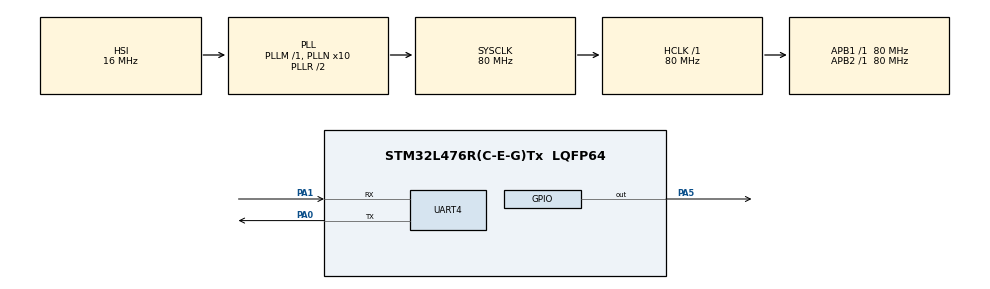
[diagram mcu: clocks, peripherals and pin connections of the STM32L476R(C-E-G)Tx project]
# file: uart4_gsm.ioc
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Dma.Request0=UART4_RX
Dma.UART4_RX.0.Direction=DMA_PERIPH_TO_MEMORY
Dma.UART4_RX.0.Instance=DMA2_Channel5
Dma.UART4_RX.0.MemDataAlignment=DMA_MDATAALIGN_BYTE
Dma.UART4_RX.0.MemInc=DMA_MINC_ENABLE
Dma.UART4_RX.0.Mode=DMA_NORMAL
Dma.UART4_RX.0.PeriphDataAlignment=DMA_PDATAALIGN_BYTE
Dma.UART4_RX.0.PeriphInc=DMA_PINC_DISABLE
Dma.UART4_RX.0.Priority=DMA_PRIORITY_LOW
Mcu.Family=STM32L4
Mcu.Name=STM32L476R(C-E-G)Tx
Mcu.Package=LQFP64
NVIC.DMA2_Channel5_IRQn=true\:0\:0\:false\:false\:true\:false\:true\:true
NVIC.PriorityGroup=NVIC_PRIORITYGROUP_4
NVIC.UART4_IRQn=true\:0\:0\:false\:false\:true\:true\:true\:true
PA0.Mode=Asynchronous
PA0.Signal=UART4_TX
PA1.Mode=Asynchronous
PA1.Signal=UART4_RX
PA5.Signal=GPIO_Output
ProjectManager.HeapSize=0x200
ProjectManager.StackSize=0x400
ProjectManager.TargetToolchain=STM32CubeIDE
RCC.ADCFreq_Value=64000000
RCC.AHBFreq_Value=80000000
RCC.APB1Freq_Value=80000000
RCC.APB1TimFreq_Value=80000000
RCC.APB2Freq_Value=80000000
RCC.APB2TimFreq_Value=80000000
RCC.CortexFreq_Value=80000000
RCC.HCLKFreq_Value=80000000
RCC.HSE_VALUE=8000000
RCC.HSI_VALUE=16000000
RCC.LSE_VALUE=32768
RCC.MSI_VALUE=4000000
RCC.PLLN=10
RCC.PLLSourceVirtual=RCC_PLLSOURCE_HSI
RCC.PREFETCH_ENABLE=1
RCC.SYSCLKFreq_VALUE=80000000
RCC.SYSCLKSource=RCC_SYSCLKSOURCE_PLLCLK
RCC.USBFreq_Value=64000000
RCC.VCOOutputFreq_Value=160000000
board=NUCLEO-L476RG

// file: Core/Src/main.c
/* USER CODE BEGIN Header */
/**
  ******************************************************************************
  * @file           : main.c
  * @brief          : Main program body
  ******************************************************************************
  * @attention
  *
  * Copyright (c) 2024 STMicroelectronics.
  * All rights reserved.
  *
  * This software is licensed under terms that can be found in the LICENSE file
  * in the root directory of this software component.
  * If no LICENSE file comes with this software, it is provided AS-IS.
  *
  ******************************************************************************
  */
/* USER CODE END Header */
#include "main.h"
#include "stdio.h"
#include "string.h"
#define RXSIZE 20
uint8_t RxBuf[30];
uint8_t string[100];
int _write(int file,char *ptr,int len)
{
    int i=0;
    for(i=0;i<len;i++)
    	ITM_SendChar((*ptr++));
    return len;
}

/* USER CODE BEGIN PTD */
UART_HandleTypeDef huart4;
/* USER CODE END PTD */

/* USER CODE BEGIN PD */
void HAL_UART_RxCpltCallback(UART_HandleTypeDef *huart)
{
  printf("Received data %s\n",RxBuf);
  memset(RxBuf,0,20);
  HAL_UART_Receive_IT(&huart4, RxBuf, 30);
}
/* USER CODE END PD */

UART_HandleTypeDef huart4;
DMA_HandleTypeDef hdma_uart4_rx;

void SystemClock_Config(void);
static void MX_GPIO_Init(void);
static void MX_DMA_Init(void);
static void MX_UART4_Init(void);

/* USER CODE BEGIN 0 */
  //  creating a buffer of 2 bytes
/* USER CODE END 0 */

int main(void)
{

  /* MCU Configuration--------------------------------------------------------*/

  /* Reset of all peripherals, Initializes the Flash interface and the Systick. */
  HAL_Init();

  /* Configure the system clock */
  SystemClock_Config();

  /* Initialize all configured peripherals */
  MX_GPIO_Init();
  MX_DMA_Init();
  MX_UART4_Init();
  /* USER CODE BEGIN 2 */
  HAL_UART_Receive_DMA(&huart4,(uint8_t *) RxBuf, 30);
  HAL_UART_Transmit(&huart4,(uint8_t *)"AT+CSQ\r\n", sizeof("AT+CSQ\r\n"), 20);
 	  printf("Sent data :AT\n");
 	  HAL_Delay (2000);
 	  HAL_GPIO_TogglePin (GPIOA, GPIO_PIN_5);
 	  HAL_Delay (250);
 	  printf("Received data :%s\n", RxBuf);
  /* USER CODE END 2 */

  /* Infinite loop */
  while (1)
  {

  }
}

void SystemClock_Config(void)
{
  RCC_OscInitTypeDef RCC_OscInitStruct = {0};
  RCC_ClkInitTypeDef RCC_ClkInitStruct = {0};

  /** Configure the main internal regulator output voltage
  */
  if (HAL_PWREx_ControlVoltageScaling(PWR_REGULATOR_VOLTAGE_SCALE1) != HAL_OK)
  {
    Error_Handler();
  }

  /** Initializes the RCC Oscillators according to the specified parameters
  * in the RCC_OscInitTypeDef structure.
  */
  RCC_OscInitStruct.OscillatorType = RCC_OSCILLATORTYPE_HSI;
  RCC_OscInitStruct.HSIState = RCC_HSI_ON;
  RCC_OscInitStruct.HSICalibrationValue = RCC_HSICALIBRATION_DEFAULT;
  RCC_OscInitStruct.PLL.PLLState = RCC_PLL_ON;
  RCC_OscInitStruct.PLL.PLLSource = RCC_PLLSOURCE_HSI;
  RCC_OscInitStruct.PLL.PLLM = 1;
  RCC_OscInitStruct.PLL.PLLN = 10;
  RCC_OscInitStruct.PLL.PLLP = RCC_PLLP_DIV7;
  RCC_OscInitStruct.PLL.PLLQ = RCC_PLLQ_DIV2;
  RCC_OscInitStruct.PLL.PLLR = RCC_PLLR_DIV2;
  if (HAL_RCC_OscConfig(&RCC_OscInitStruct) != HAL_OK)
  {
    Error_Handler();
  }

  /** Initializes the CPU, AHB and APB buses clocks
  */
  RCC_ClkInitStruct.ClockType = RCC_CLOCKTYPE_HCLK|RCC_CLOCKTYPE_SYSCLK
                              |RCC_CLOCKTYPE_PCLK1|RCC_CLOCKTYPE_PCLK2;
  RCC_ClkInitStruct.SYSCLKSource = RCC_SYSCLKSOURCE_PLLCLK;
  RCC_ClkInitStruct.AHBCLKDivider = RCC_SYSCLK_DIV1;
  RCC_ClkInitStruct.APB1CLKDivider = RCC_HCLK_DIV1;
  RCC_ClkInitStruct.APB2CLKDivider = RCC_HCLK_DIV1;

  if (HAL_RCC_ClockConfig(&RCC_ClkInitStruct, FLASH_LATENCY_4) != HAL_OK)
  {
    Error_Handler();
  }
}

static void MX_UART4_Init(void)
{

  huart4.Instance = UART4;
  huart4.Init.BaudRate = 115200;
  huart4.Init.WordLength = UART_WORDLENGTH_8B;
  huart4.Init.StopBits = UART_STOPBITS_1;
  huart4.Init.Parity = UART_PARITY_NONE;
  huart4.Init.Mode = UART_MODE_TX_RX;
  huart4.Init.HwFlowCtl = UART_HWCONTROL_NONE;
  huart4.Init.OverSampling = UART_OVERSAMPLING_16;
  huart4.Init.OneBitSampling = UART_ONE_BIT_SAMPLE_DISABLE;
  huart4.AdvancedInit.AdvFeatureInit = UART_ADVFEATURE_NO_INIT;
  if (HAL_UART_Init(&huart4) != HAL_OK)
  {
    Error_Handler();
  }

}

static void MX_DMA_Init(void)
{

  /* DMA controller clock enable */
  __HAL_RCC_DMA2_CLK_ENABLE();

  /* DMA interrupt init */
  /* DMA2_Channel5_IRQn interrupt configuration */
  HAL_NVIC_SetPriority(DMA2_Channel5_IRQn, 0, 0);
  HAL_NVIC_EnableIRQ(DMA2_Channel5_IRQn);

}

static void MX_GPIO_Init(void)
{
  GPIO_InitTypeDef GPIO_InitStruct = {0};

  /* GPIO Ports Clock Enable */
  __HAL_RCC_GPIOA_CLK_ENABLE();

  /*Configure GPIO pin Output Level */
  HAL_GPIO_WritePin(GPIOA, GPIO_PIN_5, GPIO_PIN_RESET);

  /*Configure GPIO pin : PA5 */
  GPIO_InitStruct.Pin = GPIO_PIN_5;
  GPIO_InitStruct.Mode = GPIO_MODE_OUTPUT_PP;
  GPIO_InitStruct.Pull = GPIO_NOPULL;
  GPIO_InitStruct.Speed = GPIO_SPEED_FREQ_LOW;
  HAL_GPIO_Init(GPIOA, &GPIO_InitStruct);

}

void Error_Handler(void)
{
  __disable_irq();
  while (1)
  {
  }
}
